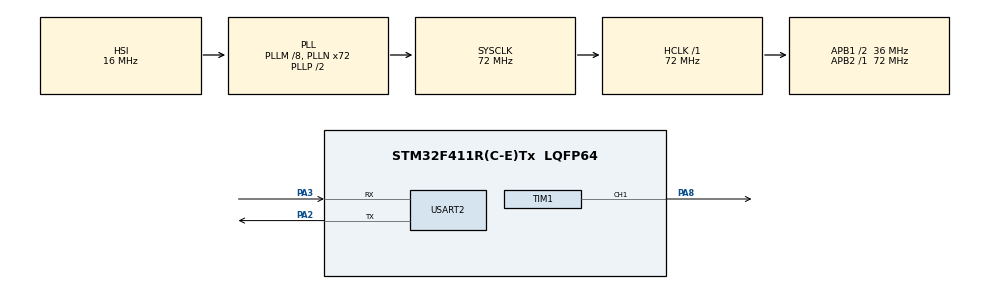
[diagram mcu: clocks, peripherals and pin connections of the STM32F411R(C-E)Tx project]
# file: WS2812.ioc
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Dma.Request0=TIM1_CH1
Dma.TIM1_CH1.0.Direction=DMA_MEMORY_TO_PERIPH
Dma.TIM1_CH1.0.FIFOMode=DMA_FIFOMODE_DISABLE
Dma.TIM1_CH1.0.Instance=DMA2_Stream1
Dma.TIM1_CH1.0.MemDataAlignment=DMA_MDATAALIGN_HALFWORD
Dma.TIM1_CH1.0.MemInc=DMA_MINC_ENABLE
Dma.TIM1_CH1.0.Mode=DMA_CIRCULAR
Dma.TIM1_CH1.0.PeriphDataAlignment=DMA_PDATAALIGN_HALFWORD
Dma.TIM1_CH1.0.PeriphInc=DMA_PINC_DISABLE
Dma.TIM1_CH1.0.Priority=DMA_PRIORITY_HIGH
Mcu.Family=STM32F4
Mcu.Name=STM32F411R(C-E)Tx
Mcu.Package=LQFP64
NVIC.DMA2_Stream1_IRQn=true\:0\:0\:false\:false\:true\:false\:true\:true
NVIC.PriorityGroup=NVIC_PRIORITYGROUP_4
NVIC.TIM3_IRQn=true\:0\:0\:false\:false\:true\:true\:true\:true
PA2.Mode=Asynchronous
PA2.Signal=USART2_TX
PA3.Mode=Asynchronous
PA3.Signal=USART2_RX
PA8.Signal=S_TIM1_CH1
ProjectManager.HeapSize=0x200
ProjectManager.StackSize=0x400
ProjectManager.TargetToolchain=STM32CubeIDE
RCC.48MHZClocksFreq_Value=36000000
RCC.AHBFreq_Value=72000000
RCC.APB1CLKDivider=RCC_HCLK_DIV2
RCC.APB1Freq_Value=36000000
RCC.APB1TimFreq_Value=72000000
RCC.APB2Freq_Value=72000000
RCC.APB2TimFreq_Value=72000000
RCC.CortexFreq_Value=72000000
RCC.HCLKFreq_Value=72000000
RCC.HSE_VALUE=25000000
RCC.HSI_VALUE=16000000
RCC.LSE_VALUE=32768
RCC.PLLM=8
RCC.PLLN=72
RCC.SYSCLKFreq_VALUE=72000000
RCC.SYSCLKSource=RCC_SYSCLKSOURCE_PLLCLK
RCC.VCOOutputFreq_Value=144000000
SH.S_TIM1_CH1.0=TIM1_CH1,PWM Generation1 CH1
TIM1.AutoReloadPreload=TIM_AUTORELOAD_PRELOAD_ENABLE
TIM1.Channel-PWM\ Generation1\ CH1=TIM_CHANNEL_1
TIM1.Period=89
TIM3.Prescaler=71
USART2.VirtualMode=VM_ASYNC
VP_TIM1_VS_ClockSourceINT.Mode=Internal
VP_TIM3_VS_ClockSourceINT.Mode=Internal
board=custom

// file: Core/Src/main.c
/* USER CODE BEGIN Header */
/**
  ******************************************************************************
  * @file           : main.c
  * @brief          : Main program body
  ******************************************************************************
  * @attention
  *
  * Copyright (c) 2025 STMicroelectronics.
  * All rights reserved.
  *
  * This software is licensed under terms that can be found in the LICENSE file
  * in the root directory of this software component.
  * If no LICENSE file comes with this software, it is provided AS-IS.
  *
  ******************************************************************************
  */
/* USER CODE END Header */
#include "main.h"

/* USER CODE BEGIN Includes */
#include "stm32f411xe.h"
#include "stm32f4xx_hal.h"
#include "ws2812.h"
#include "stdbool.h"
/* USER CODE END Includes */

TIM_HandleTypeDef htim1;
TIM_HandleTypeDef htim3;
DMA_HandleTypeDef hdma_tim1_ch1;

UART_HandleTypeDef huart2;

void SystemClock_Config(void);
static void MX_GPIO_Init(void);
static void MX_DMA_Init(void);
static void MX_TIM1_Init(void);
static void MX_USART2_UART_Init(void);
static void MX_TIM3_Init(void);

/* USER CODE BEGIN 0 */
#define WS2812_DATA_PIN GPIO_PIN_8
#define WS2812_GPIO_PORT GPIOA
//#define NUM_LEDS 4
uint32_t millisLed = 0;
void delay_ns(uint32_t ns) {
    uint32_t cycles = (72 * ns) / 10; // Convert ns to clock cycles for 72 MHz
    while (cycles--);
}

void WS2812SendBit(uint8_t bit) {
    if (bit) {
        // Send '1'
        WS2812_GPIO_PORT->BSRR = WS2812_DATA_PIN;  // Set pin high
        delay_ns(900); // 0.9 microseconds high

        WS2812_GPIO_PORT->BSRR = (uint32_t)WS2812_DATA_PIN << 16; // Reset pin low
        delay_ns(350); // 0.35 microseconds low
    } else {
        // Send '0'
        WS2812_GPIO_PORT->BSRR = WS2812_DATA_PIN;  // Set pin high
        delay_ns(350); // 0.35 microseconds high

        WS2812_GPIO_PORT->BSRR = (uint32_t)WS2812_DATA_PIN << 16; // Reset pin low
        delay_ns(900); // 0.9 microseconds low
    }
}

void WS2812SendByte(uint8_t byte) {
    for (int i = 0; i < 8; i++) {
        WS2812SendBit((byte << i) & 0x80);
    }
}

void WS2812SendColor(uint8_t r, uint8_t g, uint8_t b) {
    WS2812SendByte(g); // Send green byte
    WS2812SendByte(r); // Send red byte
    WS2812SendByte(b); // Send blue byte
}

void WS2812SendColors(uint8_t colors[][3], uint8_t num_leds) {
    for (uint8_t i = 0; i < num_leds; i++) {
        WS2812SendColor(colors[i][0], colors[i][1], colors[i][2]);
    }
}
/* USER CODE END 0 */

int main(void)
{

  /* MCU Configuration--------------------------------------------------------*/

  /* Reset of all peripherals, Initializes the Flash interface and the Systick. */
  HAL_Init();

  /* Configure the system clock */
  SystemClock_Config();

  /* Initialize all configured peripherals */
  MX_GPIO_Init();
  MX_DMA_Init();
  MX_TIM1_Init();
  MX_USART2_UART_Init();
  MX_TIM3_Init();
  /* USER CODE BEGIN 2 */
  HAL_TIM_Base_Start_IT(&htim3);
  uint8_t led_colors[NUM_LEDS][3] = {
            {0, 0, 0},  // Red
            {0, 0, 0},  // Green
            {0, 0, 0},  // Blue
            {0, 0, 0} // Yellow
        };
 // WS2812SendColors(led_colors, NUM_LEDS);
  ws2812_init(&htim1, &hdma_tim1_ch1, TIM_CHANNEL_1);
  ws2812_set_colors(&htim1, (uint32_t*)led_colors, NUM_LEDS);
  HAL_Delay(2000); // 500 ms delay[
  update_single_led(6,0,64,0);
  HAL_Delay(2000); // 500 ms delay[

  bool ledStatus =false;
  /* USER CODE END 2 */

  /* Infinite loop */
  /* USER CODE BEGIN WHILE */
  while (1)
  {

	  if(!ledStatus){
		  update_single_led(4,64,0,0);
	  }else update_single_led(4,0,0,0);
	  ledStatus = !ledStatus;
	  HAL_Delay(500);
    /* USER CODE END WHILE */

  }
}

void SystemClock_Config(void)
{
  RCC_OscInitTypeDef RCC_OscInitStruct = {0};
  RCC_ClkInitTypeDef RCC_ClkInitStruct = {0};

  /** Configure the main internal regulator output voltage
  */
  __HAL_RCC_PWR_CLK_ENABLE();
  __HAL_PWR_VOLTAGESCALING_CONFIG(PWR_REGULATOR_VOLTAGE_SCALE1);

  /** Initializes the RCC Oscillators according to the specified parameters
  * in the RCC_OscInitTypeDef structure.
  */
  RCC_OscInitStruct.OscillatorType = RCC_OSCILLATORTYPE_HSI;
  RCC_OscInitStruct.HSIState = RCC_HSI_ON;
  RCC_OscInitStruct.HSICalibrationValue = RCC_HSICALIBRATION_DEFAULT;
  RCC_OscInitStruct.PLL.PLLState = RCC_PLL_ON;
  RCC_OscInitStruct.PLL.PLLSource = RCC_PLLSOURCE_HSI;
  RCC_OscInitStruct.PLL.PLLM = 8;
  RCC_OscInitStruct.PLL.PLLN = 72;
  RCC_OscInitStruct.PLL.PLLP = RCC_PLLP_DIV2;
  RCC_OscInitStruct.PLL.PLLQ = 4;
  if (HAL_RCC_OscConfig(&RCC_OscInitStruct) != HAL_OK)
  {
    Error_Handler();
  }

  /** Initializes the CPU, AHB and APB buses clocks
  */
  RCC_ClkInitStruct.ClockType = RCC_CLOCKTYPE_HCLK|RCC_CLOCKTYPE_SYSCLK
                              |RCC_CLOCKTYPE_PCLK1|RCC_CLOCKTYPE_PCLK2;
  RCC_ClkInitStruct.SYSCLKSource = RCC_SYSCLKSOURCE_PLLCLK;
  RCC_ClkInitStruct.AHBCLKDivider = RCC_SYSCLK_DIV1;
  RCC_ClkInitStruct.APB1CLKDivider = RCC_HCLK_DIV2;
  RCC_ClkInitStruct.APB2CLKDivider = RCC_HCLK_DIV1;

  if (HAL_RCC_ClockConfig(&RCC_ClkInitStruct, FLASH_LATENCY_2) != HAL_OK)
  {
    Error_Handler();
  }
}

static void MX_TIM1_Init(void)
{

  TIM_ClockConfigTypeDef sClockSourceConfig = {0};
  TIM_MasterConfigTypeDef sMasterConfig = {0};
  TIM_OC_InitTypeDef sConfigOC = {0};
  TIM_BreakDeadTimeConfigTypeDef sBreakDeadTimeConfig = {0};

  htim1.Instance = TIM1;
  htim1.Init.Prescaler = 0;
  htim1.Init.CounterMode = TIM_COUNTERMODE_UP;
  htim1.Init.Period = 89;
  htim1.Init.ClockDivision = TIM_CLOCKDIVISION_DIV1;
  htim1.Init.RepetitionCounter = 0;
  htim1.Init.AutoReloadPreload = TIM_AUTORELOAD_PRELOAD_ENABLE;
  if (HAL_TIM_Base_Init(&htim1) != HAL_OK)
  {
    Error_Handler();
  }
  sClockSourceConfig.ClockSource = TIM_CLOCKSOURCE_INTERNAL;
  if (HAL_TIM_ConfigClockSource(&htim1, &sClockSourceConfig) != HAL_OK)
  {
    Error_Handler();
  }
  if (HAL_TIM_PWM_Init(&htim1) != HAL_OK)
  {
    Error_Handler();
  }
  sMasterConfig.MasterOutputTrigger = TIM_TRGO_RESET;
  sMasterConfig.MasterSlaveMode = TIM_MASTERSLAVEMODE_DISABLE;
  if (HAL_TIMEx_MasterConfigSynchronization(&htim1, &sMasterConfig) != HAL_OK)
  {
    Error_Handler();
  }
  sConfigOC.OCMode = TIM_OCMODE_PWM1;
  sConfigOC.Pulse = 0;
  sConfigOC.OCPolarity = TIM_OCPOLARITY_HIGH;
  sConfigOC.OCNPolarity = TIM_OCNPOLARITY_HIGH;
  sConfigOC.OCFastMode = TIM_OCFAST_DISABLE;
  sConfigOC.OCIdleState = TIM_OCIDLESTATE_RESET;
  sConfigOC.OCNIdleState = TIM_OCNIDLESTATE_RESET;
  if (HAL_TIM_PWM_ConfigChannel(&htim1, &sConfigOC, TIM_CHANNEL_1) != HAL_OK)
  {
    Error_Handler();
  }
  sBreakDeadTimeConfig.OffStateRunMode = TIM_OSSR_DISABLE;
  sBreakDeadTimeConfig.OffStateIDLEMode = TIM_OSSI_DISABLE;
  sBreakDeadTimeConfig.LockLevel = TIM_LOCKLEVEL_OFF;
  sBreakDeadTimeConfig.DeadTime = 0;
  sBreakDeadTimeConfig.BreakState = TIM_BREAK_DISABLE;
  sBreakDeadTimeConfig.BreakPolarity = TIM_BREAKPOLARITY_HIGH;
  sBreakDeadTimeConfig.AutomaticOutput = TIM_AUTOMATICOUTPUT_DISABLE;
  if (HAL_TIMEx_ConfigBreakDeadTime(&htim1, &sBreakDeadTimeConfig) != HAL_OK)
  {
    Error_Handler();
  }
  HAL_TIM_MspPostInit(&htim1);

}

static void MX_TIM3_Init(void)
{

  TIM_ClockConfigTypeDef sClockSourceConfig = {0};
  TIM_MasterConfigTypeDef sMasterConfig = {0};

  htim3.Instance = TIM3;
  htim3.Init.Prescaler = 71;
  htim3.Init.CounterMode = TIM_COUNTERMODE_UP;
  htim3.Init.Period = 65535;
  htim3.Init.ClockDivision = TIM_CLOCKDIVISION_DIV1;
  htim3.Init.AutoReloadPreload = TIM_AUTORELOAD_PRELOAD_DISABLE;
  if (HAL_TIM_Base_Init(&htim3) != HAL_OK)
  {
    Error_Handler();
  }
  sClockSourceConfig.ClockSource = TIM_CLOCKSOURCE_INTERNAL;
  if (HAL_TIM_ConfigClockSource(&htim3, &sClockSourceConfig) != HAL_OK)
  {
    Error_Handler();
  }
  sMasterConfig.MasterOutputTrigger = TIM_TRGO_RESET;
  sMasterConfig.MasterSlaveMode = TIM_MASTERSLAVEMODE_DISABLE;
  if (HAL_TIMEx_MasterConfigSynchronization(&htim3, &sMasterConfig) != HAL_OK)
  {
    Error_Handler();
  }

}

static void MX_USART2_UART_Init(void)
{

  huart2.Instance = USART2;
  huart2.Init.BaudRate = 115200;
  huart2.Init.WordLength = UART_WORDLENGTH_8B;
  huart2.Init.StopBits = UART_STOPBITS_1;
  huart2.Init.Parity = UART_PARITY_NONE;
  huart2.Init.Mode = UART_MODE_TX_RX;
  huart2.Init.HwFlowCtl = UART_HWCONTROL_NONE;
  huart2.Init.OverSampling = UART_OVERSAMPLING_16;
  if (HAL_UART_Init(&huart2) != HAL_OK)
  {
    Error_Handler();
  }

}

static void MX_DMA_Init(void)
{

  /* DMA controller clock enable */
  __HAL_RCC_DMA2_CLK_ENABLE();

  /* DMA interrupt init */
  /* DMA2_Stream1_IRQn interrupt configuration */
  HAL_NVIC_SetPriority(DMA2_Stream1_IRQn, 0, 0);
  HAL_NVIC_EnableIRQ(DMA2_Stream1_IRQn);

}

static void MX_GPIO_Init(void)
{

  /* GPIO Ports Clock Enable */
  __HAL_RCC_GPIOA_CLK_ENABLE();

}

/* USER CODE BEGIN 4 */
void HAL_TIM_PeriodElapsedCallback(TIM_HandleTypeDef *htim) {
    if (htim->Instance == TIM3) {
        // Increment your variable here every 100ms
        millisLed++;
        static bool ledBlue = false;
        if(millisLed>= 3){
        	millisLed = 0;
        	if(!ledBlue){
        		update_single_led(2, 0, 0,64);
        	}else update_single_led(2, 0, 0,0);
        	ledBlue = !ledBlue;

        }
    }
}
/* USER CODE END 4 */

void Error_Handler(void)
{
  __disable_irq();
  while (1)
  {
  }
}
